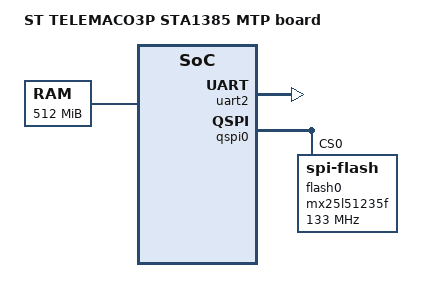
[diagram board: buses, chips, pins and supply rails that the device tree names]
/*
 * Copyright (C) 2016 STMicroelectronics
 * Author: Shija PS <shija.ps@st.com>
 *
 * This program is free software; you can redistribute it and/or modify
 * it under the terms of the GNU General Public License version 2, as
 * published by the Free Software Foundation.
 */

/dts-v1/;
#include "sta1295.dtsi"

/ {
	model = "ST TELEMACO3P STA1385 MTP board";
	compatible = "st,sta1385-mtp";

	aliases {
		spi0 = &qspi0;
	};

	chosen {
                stdout-path = &uart2;
        };

	memory@A0000000 {
		device_type = "memory";
		reg = <0xa0000000 0x20000000>;
	};

	soc {
		uart2: uart@50010000 {
			clock = <52000000>;
			status = "okay";
		};

		uart3: uart@50020000 {
			clock = <52000000>;
			status = "disabled";
		};

	};
};

&qspi0 {
	bus-num = <0>;
	status = "okay";

	/* 64MB serial flash memory */
	flash0: mx25l51235f@0 {
		compatible = "spi-flash";
		#address-cells = <1>;
		#size-cells = <1>;
		reg = <0>;
		spi-max-frequency = <133000000>;
		spi-tx-bus-width = <4>; /* TX quad mode */
		spi-rx-bus-width = <4>; /* RX quad mode */
		memory-map = <0x90000000 0x08000000>;
	};
};
